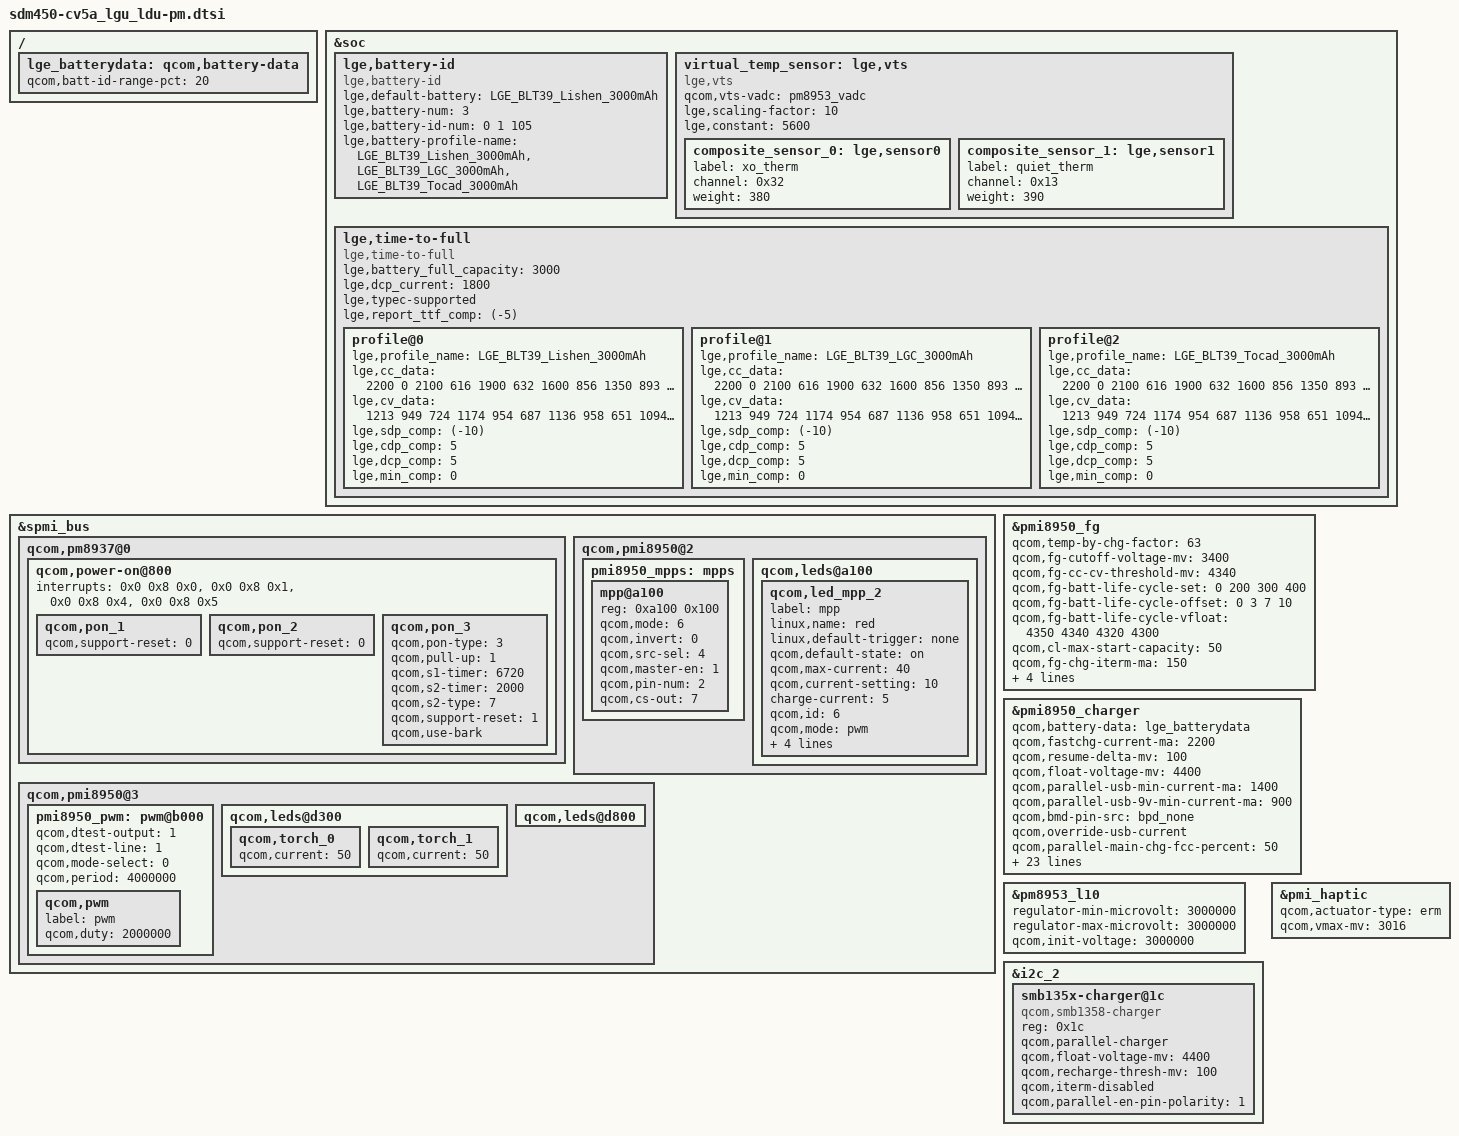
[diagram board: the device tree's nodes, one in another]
/*
 * Copyright (c) 2017, The Linux Foundation. All rights reserved.
 *
 * This program is free software; you can redistribute it and/or modify
 * it under the terms of the GNU General Public License version 2 and
 * only version 2 as published by the Free Software Foundation.
 *
 * This program is distributed in the hope that it will be useful,
 * but WITHOUT ANY WARRANTY; without even the implied warranty of
 * MERCHANTABILITY or FITNESS FOR A PARTICULAR PURPOSE.  See the
 * GNU General Public License for more details.
 */

/{
	lge_batterydata: qcom,battery-data {
		qcom,batt-id-range-pct = <20>;
		#include "../battery_profile/LGE_BLT39_Lishen_3000mAh.dtsi"
		#include "../battery_profile/LGE_BLT39_LGC_3000mAh.dtsi"
		#include "../battery_profile/LGE_BLT39_Tocad_3000mAh.dtsi"
	};
};

&soc {
	lge,battery-id{
		compatible = "lge,battery-id";
		/delete-property/ lge,restrict-mode-enabled;
		/*default battery profile*/
		lge,default-battery = "LGE_BLT39_Lishen_3000mAh";
		/*Total number of combined of battery cell and battery id */
		lge,battery-num = <3>;
		/* battery id and battery profile match numbers */
		lge,battery-id-num = <0 1 105>;
		/* battery profile */
		lge,battery-profile-name = "LGE_BLT39_Lishen_3000mAh",
						"LGE_BLT39_LGC_3000mAh",
						"LGE_BLT39_Tocad_3000mAh";
	};

	/* vts = (0.38*xo_therm) + (0.39*quiet_therm) + (5.6) */
	virtual_temp_sensor: lge,vts {
		compatible = "lge,vts";
		qcom,vts-vadc = <&pm8953_vadc>;
		lge,scaling-factor= <10>;
		lge,constant = <5600>;
		composite_sensor_0: lge,sensor0 {
			label = "xo_therm";
			channel = <0x32>;
			weight = <380>;
		};
		composite_sensor_1: lge,sensor1 {
			label = "quiet_therm";
			channel = <0x13>;
			weight = <390>;
		};
	};

	/* time to full */
	lge,time-to-full {
		compatible = "lge,time-to-full";
		lge,battery_full_capacity = <3000>;
		lge,dcp_current = <1800>;
		lge,typec-supported;
		/delete-property/lge,hvdcp-supported;
		/delete-property/lge,hvdcp3-supported;
		/delete-property/lge,parallel-supported;
		lge,report_ttf_comp = <(-5)>;
		profile@0 {
			lge,profile_name = "LGE_BLT39_Lishen_3000mAh";
				    /* current  soc */
			lge,cc_data = < 2200	0
					2100	616
					1900	632
					1600	856
					1350	893
					1175	924>;
				    /* current  soc    time */
			lge,cv_data = < 1213	949	724
					1174	954	687
					1136	958	651
					1094	962	611
					1067	966	571
					1025	970	530
					985	973	486
					956	977	441
					915	980	394
					880	983	345
					843	986	295
					812	989	241
					777	992	186
					743	995	129
					706	998	66
					672	1000	0>;
			lge,sdp_comp = <(-10)>;
			lge,cdp_comp = <5>;
			lge,dcp_comp = <5>;
			lge,min_comp = <0>;
		};
		profile@1 {
			lge,profile_name = "LGE_BLT39_LGC_3000mAh";
				    /* current  soc */
			lge,cc_data = < 2200	0
					2100	616
					1900	632
					1600	856
					1350	893
					1175	924>;
				    /* current  soc    time */
			lge,cv_data = < 1213	949	724
					1174	954	687
					1136	958	651
					1094	962	611
					1067	966	571
					1025	970	530
					985	973	486
					956	977	441
					915	980	394
					880	983	345
					843	986	295
					812	989	241
					777	992	186
					743	995	129
					706	998	66
					672	1000	0>;
			lge,sdp_comp = <(-10)>;
			lge,cdp_comp = <5>;
			lge,dcp_comp = <5>;
			lge,min_comp = <0>;
		};
		profile@2 {
			lge,profile_name = "LGE_BLT39_Tocad_3000mAh";
				    /* current  soc */
			lge,cc_data = < 2200	0
					2100	616
					1900	632
					1600	856
					1350	893
					1175	924>;
				    /* current  soc    time */
			lge,cv_data = < 1213	949	724
					1174	954	687
					1136	958	651
					1094	962	611
					1067	966	571
					1025	970	530
					985	973	486
					956	977	441
					915	980	394
					880	983	345
					843	986	295
					812	989	241
					777	992	186
					743	995	129
					706	998	66
					672	1000	0>;
			lge,sdp_comp = <(-10)>;
			lge,cdp_comp = <5>;
			lge,dcp_comp = <5>;
			lge,min_comp = <0>;
		};
	};
};

&spmi_bus {
	qcom,pm8937@0 {
		qcom,power-on@800 {
			interrupts = <0x0 0x8 0x0>,
				     <0x0 0x8 0x1>,
				     <0x0 0x8 0x4>,
				     <0x0 0x8 0x5>;
			interrupt-names = "kpdpwr", "resin",
				"resin-bark", "kpdpwr-resin-bark";

			qcom,pon_1 {
				status = "ok";
				qcom,support-reset = <0>;
			};
			qcom,pon_2 {
				status = "ok";
				qcom,support-reset = <0>;
			};
			qcom,pon_3 {
				status = "ok";
				qcom,pon-type = <3>;
				qcom,pull-up = <1>;
				qcom,s1-timer = <6720>;
				qcom,s2-timer = <2000>;
				qcom,s2-type = <7>;
				qcom,support-reset = <1>;
				qcom,use-bark;
			};
		};
	};

	qcom,pmi8950@2 {
		pmi8950_mpps: mpps {
			mpp@a100 {
				status = "okay";
				reg = <0xa100 0x100>;
				qcom,mode = <6>;
				qcom,invert = <0>;
				qcom,src-sel = <4>;
				qcom,master-en = <1>;
				qcom,pin-num = <2>;
				qcom,cs-out = <7>;
			};
		};
		qcom,leds@a100 {
			status = "okay";
			qcom,led_mpp_2 {
				label = "mpp";
				linux,name = "red";
				linux,default-trigger = "none";
				qcom,default-state = "on";
				qcom,max-current = <40>;
				qcom,current-setting = <10>;
				charge-current = <5>;
				qcom,id = <6>;
				qcom,mode = "pwm";
				qcom,pwm-us = <1000>;
				qcom,source-sel = <8>;
				qcom,mode-ctrl = <0x60>;
				pwms = <&pmi8950_pwm 0 0>;
			};
		};
	};

	qcom,pmi8950@3 {
		pmi8950_pwm: pwm@b000 {
			status = "ok";
			qcom,dtest-output = <1>;
			qcom,dtest-line = <1>;
			qcom,mode-select = <0>;
			qcom,period = <4000000>;
			qcom,pwm {
				label = "pwm";
				qcom,duty = <2000000>;
			};
		};
		qcom,leds@d300 {
			qcom,torch_0 {
				qcom,current = <50>;
			};
			qcom,torch_1 {
				qcom,current = <50>;
			};
		};
		qcom,leds@d800 {
			/delete-property/ qcom,en-ext-pfet-sc-pro;
		};
	};
};

&pmi8950_fg {
	qcom,temp-by-chg-factor = <63>;
	qcom,fg-cutoff-voltage-mv = <3400>;
	qcom,fg-cc-cv-threshold-mv = <4340>;
	qcom,fg-batt-life-cycle-set = <0 200 300 400>;
	qcom,fg-batt-life-cycle-offset = <0 3 7 10>;
	qcom,fg-batt-life-cycle-vfloat = <4350 4340 4320 4300>;
	qcom,cl-max-start-capacity = <50>;
	qcom,fg-chg-iterm-ma = <150>;
	lge_batt_vts_raw = <325>;
	lge_batt_vts_xo = <190>;
	lge_batt_vts_quiet = <455>;
	lge_batt_vts_constant = <(-7)>;
};

&pmi8950_charger {
	qcom,battery-data = <&lge_batterydata>;
	qcom,fastchg-current-ma = <2200>;
	qcom,resume-delta-mv = <100>;
	qcom,float-voltage-mv = <4400>;
	qcom,parallel-usb-min-current-ma = <1400>;
	qcom,parallel-usb-9v-min-current-ma = <900>;
	qcom,bmd-pin-src = "bpd_none";
	qcom,override-usb-current;
	qcom,parallel-main-chg-fcc-percent = <50>;
	qcom,parallel-main-chg-icl-percent = <50>;
	qcom,maximum-icl-ma = <2000>;
	lge,jeita-disabled;
	/delete-property/lge,parallel-supported;
	lge,hvdcp-not-supported;
	qcom,batt-life-cycle-fcc-ma = <2200 2100 2000 1900>;
	qcom,fg-batt-life-cycle-vfloat = <4400 4380 4360 4340>;
	qcom,usb_pin-vadc = <&pmi8950_vadc>;


	lge,no-init-cable = <0 0 0>;

	/* ref resistance 1.8V, 200K */
	lge,cable-56k-1v8-200k = <600000 1500 1500>;
	lge,cable-130k-1v8-200k = <780000 1500 1500>;
	lge,cable-910k-1v8-200k = <1630000 1500 1500>;
	lge,cable-none-1v8-200k = <1900000 1800  500>;

	/* ref resistance 1V, 100K */
	lge,cable-56k-1v0-100k =  <500000 1500 1500>;
	lge,cable-130k-1v0-100k = <700000 1500 1500>;
	lge,cable-910k-1v0-100k = <950000 1500 1500>;
	lge,cable-none-1v0-100k = <1100000 1800  500>;

	lge,usb-max-current-ma = <1800>;
	lge,iusb-qc20 = <1800 1800>;
	lge,ibat-qc20 = <2200 1000>;
	lge,otp-warm-ibat = <900>;
	lge,otp-cold-ibat = <900>;
};

&pm8953_l10 {
        regulator-min-microvolt = <3000000>;
        regulator-max-microvolt = <3000000>;
        qcom,init-voltage = <3000000>;
};

&i2c_2 {
	/* Parallel-charger configuration */
	smb135x-charger@1c{
		compatible = "qcom,smb1358-charger";
		reg = <0x1c>;
		qcom,parallel-charger;
		qcom,float-voltage-mv = <4400>;
		qcom,recharge-thresh-mv = <100>;
		qcom,iterm-disabled;
		qcom,parallel-en-pin-polarity = <1>;
	};
};

&pmi_haptic{
	status = "okay";
	qcom,actuator-type = "erm";
	qcom,vmax-mv = <3016>;
};


